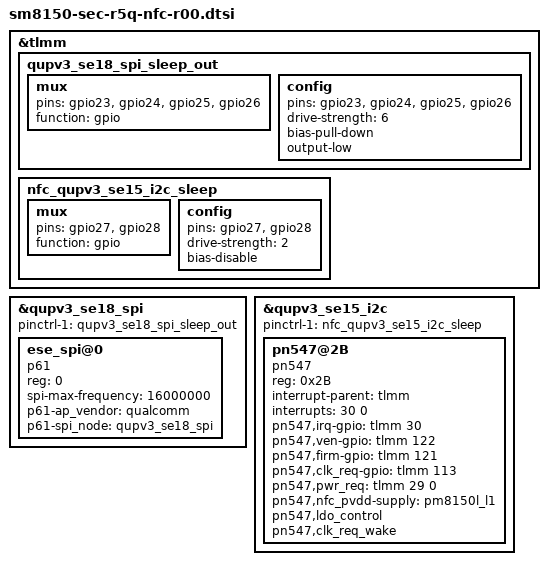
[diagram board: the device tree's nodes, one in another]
/*
 * This program is free software; you can redistribute it and/or modify
 * it under the terms of the GNU General Public License version 2 and
 * only version 2 as published by the Free Software Foundation.
 *
 * This program is distributed in the hope that it will be useful,
 * but WITHOUT ANY WARRANTY; without even the implied warranty of
 * MERCHANTABILITY or FITNESS FOR A PARTICULAR PURPOSE.  See the
 * GNU General Public License for more details.
 */
&tlmm {
	qupv3_se18_spi_sleep_out: qupv3_se18_spi_sleep_out {
		mux {
			pins = "gpio23", "gpio24", "gpio25",
				"gpio26";
			function = "gpio";
		};

		config {
			pins = "gpio23", "gpio24", "gpio25",
				"gpio26";
			drive-strength = <6>;
			bias-pull-down; /* pull down */
			output-low;
		};
	};

	nfc_qupv3_se15_i2c_sleep: nfc_qupv3_se15_i2c_sleep {
	      mux {
		      pins = "gpio27", "gpio28";
		      function = "gpio";
	      };

	      config {
		      pins = "gpio27", "gpio28";
		      drive-strength = <2>;
		      bias-disable;
	      };
	};
};

/* gpio 23, 24, 25, 26 are for eSE spi */
&qupv3_se18_spi {
	status = "ok";
	/* /delete-property/ pinctrl-1; */
	pinctrl-1 = <&qupv3_se18_spi_sleep_out>;
	ese_spi@0 {
		compatible = "p61";
		reg = <0>;
		spi-max-frequency = <16000000>;
		p61-ap_vendor = "qualcomm";
		p61-spi_node = <&qupv3_se18_spi>;
		/* ese-det-gpio = <&tlmm xxx 0>; */ /* for checking if this model supports eSE or not */
		/* pinctrl-names = "default"; */
		/* pinctrl-0 = <&ese_det_gpio>; */
	};
};

/* gpio 27, 28 are for NFC i2c */
&qupv3_se15_i2c {
	status = "ok";
	pinctrl-1 = <&nfc_qupv3_se15_i2c_sleep>;
	pn547@2B {
		compatible = "pn547";
		reg = <0x2B>;
		interrupt-parent = <&tlmm>;
		interrupts = <30 0>;
		pn547,irq-gpio = <&tlmm 30 0>;
		pn547,ven-gpio = <&tlmm 122 0>;
		pn547,firm-gpio = <&tlmm 121 0>;
		pn547,clk_req-gpio = <&tlmm 113 0>;
		pn547,pwr_req =  <&tlmm 29 0>;
		pn547,nfc_pvdd-supply = <&pm8150l_l1>;
		pn547,ldo_control;
		pn547,clk_req_wake;
/*		pn547,nfc_pm_clk; */ /* don't need to control bbclk3 by driver code, if MGPI is enabled */
/*		clocks = <&clock_rpmh RPMH_LN_BB_CLK3>; */
/*		clock-names = "rf_clk"; */
/*		qcom,clk-src = "BBCLK3"; */
/*		pinctrl-names = "default"; */
/*		pinctrl-0 = <&nfc_clk_default>; */
	};
};
